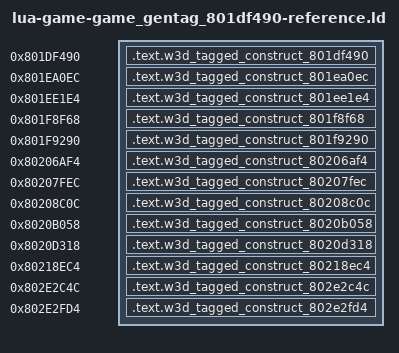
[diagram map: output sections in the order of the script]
/* Generated reference-only placements. All bodies are source-built. */
OUTPUT_FORMAT("elf32-powerpc")
OUTPUT_ARCH(powerpc)
ENTRY(w3d_tagged_construct_801df490)
_SDA_BASE_ = 0x804b2540;
_SDA2_BASE_ = 0x804c2540;
w3d_vtable_80411590 = 0x80411590;
w3d_vtable_80411ac0 = 0x80411ac0;
w3d_vtable_80416c48 = 0x80416c48;
w3d_vtable_80416c80 = 0x80416c80;
w3d_vtable_80417168 = 0x80417168;
w3d_vtable_80417700 = 0x80417700;
w3d_vtable_80418140 = 0x80418140;
w3d_vtable_80418168 = 0x80418168;
w3d_vtable_80418190 = 0x80418190;
w3d_vtable_804181c0 = 0x804181c0;
w3d_vtable_80419180 = 0x80419180;
w3d_vtable_80419238 = 0x80419238;
w3d_vtable_80419268 = 0x80419268;
w3d_vtable_80419318 = 0x80419318;
w3d_vtable_80419348 = 0x80419348;
w3d_vtable_804194a0 = 0x804194a0;
w3d_vtable_804194d0 = 0x804194d0;
w3d_vtable_80419778 = 0x80419778;
w3d_vtable_8041ca60 = 0x8041ca60;
w3d_vtable_8041cab8 = 0x8041cab8;
w3d_vtable_8041cb18 = 0x8041cb18;
w3d_vtable_8041cb40 = 0x8041cb40;
SECTIONS {
  .text.w3d_tagged_construct_801df490 0x801df490 : { *(.text.w3d_tagged_construct_801df490) }
  .text.w3d_tagged_construct_801ea0ec 0x801ea0ec : { *(.text.w3d_tagged_construct_801ea0ec) }
  .text.w3d_tagged_construct_801ee1e4 0x801ee1e4 : { *(.text.w3d_tagged_construct_801ee1e4) }
  .text.w3d_tagged_construct_801f8f68 0x801f8f68 : { *(.text.w3d_tagged_construct_801f8f68) }
  .text.w3d_tagged_construct_801f9290 0x801f9290 : { *(.text.w3d_tagged_construct_801f9290) }
  .text.w3d_tagged_construct_80206af4 0x80206af4 : { *(.text.w3d_tagged_construct_80206af4) }
  .text.w3d_tagged_construct_80207fec 0x80207fec : { *(.text.w3d_tagged_construct_80207fec) }
  .text.w3d_tagged_construct_80208c0c 0x80208c0c : { *(.text.w3d_tagged_construct_80208c0c) }
  .text.w3d_tagged_construct_8020b058 0x8020b058 : { *(.text.w3d_tagged_construct_8020b058) }
  .text.w3d_tagged_construct_8020d318 0x8020d318 : { *(.text.w3d_tagged_construct_8020d318) }
  .text.w3d_tagged_construct_80218ec4 0x80218ec4 : { *(.text.w3d_tagged_construct_80218ec4) }
  .text.w3d_tagged_construct_802e2c4c 0x802e2c4c : { *(.text.w3d_tagged_construct_802e2c4c) }
  .text.w3d_tagged_construct_802e2fd4 0x802e2fd4 : { *(.text.w3d_tagged_construct_802e2fd4) }
  /DISCARD/ : { *(.text*) *(.rodata*) *(.data*) *(.bss*) *(.sdata*) *(.sbss*) *(.comment) }
}
